# STM32H533 register map
File version: 1.3
CPU: CM33 r0p0, little endian, MPU, FPU, 4 interrupt priority bits
Registers are 32-bit, read-write, reset 0x0 unless marked. A register's access mark holds for its fields unless they carry their own. Offsets are from the block's base; [hi:lo] are bit positions; {n}, {i} and the like mark numbered series; 'fields as' and 'values as' point back to an identical list.

## PWR — PWR address block description
Base 0x44020800
Same registers: PWR_S 0x54020800
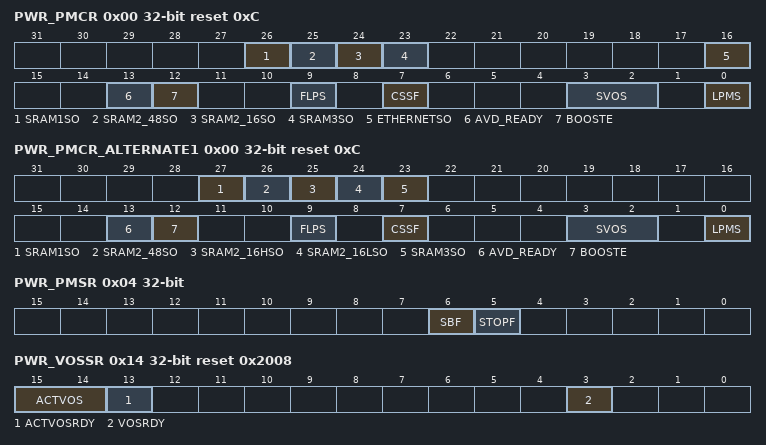
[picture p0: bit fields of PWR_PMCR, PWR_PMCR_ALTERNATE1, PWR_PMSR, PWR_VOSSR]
0x00 PWR_PMCR reset 0xC — PWR power mode control register
  [26] SRAM1SO — AHB SRAM1 shut-off in Stop mode
    0=AHB RA; 1=AHB RAM1 content is lost in Stop mode
  [25] SRAM2_48SO — AHB SRAM2 48-Kbyte shut-off in Stop mode.
    0=AHB RAM2 48-Kbyte content is kept in Stop mode; 1=AHB RAM2 48-Kbyte content is lost in Stop mode
  [24] SRAM2_16SO — AHB SRAM2 16-Kbyte shut-off in Stop mode.
    0=AHB RAM2 16-Kbyte content is kept in Stop mode; 1=AHB RAM2 16-Kbyte content is lost in Stop mode
  [23] SRAM3SO — AHB SRAM3 shut-off in Stop mode.
    0=AHB RAM3 content is kept in Stop mode; 1=AHB RAM3 content is lost in Stop mode
  [16] ETHERNETSO — ETHERNET RAM shut-off in Stop mode.
    0=ETHERNET RAM content is kept in Stop mode; 1=ETHERNET RAM content is lost in Stop mode
  [13] AVD_READY — analog voltage ready
    0=peripheral analog voltage Vless thansub>DDAless than/sub> not ready (default); 1=peripheral analog voltage Vless thansub>DDAless than/sub> ready
  [12] BOOSTE — analog switch Vless thansub>BOOSTless than/sub> control
    0=booster disabled (default); 1=booster enabled if analog voltage ready (AVD_READY = 1)
  [9] FLPS — flash memory low-power mode in Stop mode
    0=flash memory remains in normal mode when the system enters Stop mode (quick restart time); 1=flash memory enters low-power mode when the system enters Stop mode(low-power consumption)
  [7] CSSF — clear Standby and Stop flags (always read as 0)
    0=no effect; 1=STOPF and SBF flags cleared
  [3:2] SVOS — system Stop mode voltage scaling selection
    1=SVOS5 scale 5; 2=SVOS4 scale 4; 3=SVOS3 scale 3 (default)
  [0] LPMS — low-power mode selection
    0=keeps Stop mode when entering DeepSleep; 1=allows Standby mode when entering DeepSleep
0x00 PWR_PMCR_ALTERNATE1 reset 0xC (alternate view of PWR_PMCR) — PWR power mode control register
  [27] SRAM1SO — AHB SRAM1 shut-off in Stop mode
    0=AHB RA; 1=AHB RAM1 content is lost in Stop mode
  [26] SRAM2_48SO — AHB SRAM2 48-Kbyte shut-off in Stop mode.
    values as PWR_PMCR.SRAM2_48SO
  [25] SRAM2_16HSO — AHB SRAM2 high 16-Kbyte shut-off in Stop mode.
    0=AHB RAM2 high 16-Kbyte content is kept in Stop mode; 1=AHB RAM2 ]high16-Kbyte content is lost in Stop mode
  [24] SRAM2_16LSO — AHB SRAM2 low 16-Kbyte shut-off in Stop mode.
    0=AHB RAM2 low 16-Kbyte content is kept in Stop mode; 1=AHB RAM2 low 16-Kbyte content is lost in Stop mode
  [23] SRAM3SO — AHB SRAM3 shut-off in Stop mode.
    values as PWR_PMCR.SRAM3SO
  [13] AVD_READY — analog voltage ready
    values as PWR_PMCR.AVD_READY
  [12] BOOSTE — analog switch Vless thansub>BOOSTless than/sub> control
    values as PWR_PMCR.BOOSTE
  [9] FLPS — flash memory low-power mode in Stop mode
    values as PWR_PMCR.FLPS
  [7] CSSF — clear Standby and Stop flags (always read as 0)
    0=no effect; 1=STOPF and SBF flags cleared
  [3:2] SVOS — system Stop mode voltage scaling selection
    1=SVOS5 scale 5; 2=SVOS4 scale 4; 3=SVOS3 scale 3 (default)
  [0] LPMS — low-power mode selection
    values as PWR_PMCR.LPMS
0x04 PWR_PMSR ro — PWR status register
  [6] SBF — System standby flag
    0=system has not been in Standby mode; 1=system has been in Standby mode
  [5] STOPF — Stop flag
    0=system has not been in Stop mode; 1=system has been in Stop mode
0x10 PWR_VOSCR — PWR voltage scaling control register
  [5:4] VOS — voltage scaling selection according to performance
    0=scale 3 (default); 1=scale 2; 2=scale 1; 3=scale 0
0x14 PWR_VOSSR ro reset 0x2008 — PWR voltage scaling status register
  [15:14] ACTVOS — voltage output scaling currently applied to Vless thansub>COREless than/sub>
    0=VOS3 (lowest power); 1=VOS2; 2=VOS1; 3=VOS0 (highest frequency)
  [13] ACTVOSRDY — Voltage level ready for currently used VOS
    0=Vless thansub>COREless than/sub> is above or below the current voltage scaling provided by ACTVOS[1:0]; 1=Vless thansub>COREless than/sub> is equal to the current voltage scaling provided by ACTVOS[1:0]
  [3] VOSRDY — Ready bit for Vless thansub>COREless than/sub> voltage scaling output selection.
    0=Not ready, voltage level below VOS selected level; 1=Ready, voltage level at or above VOS selected level
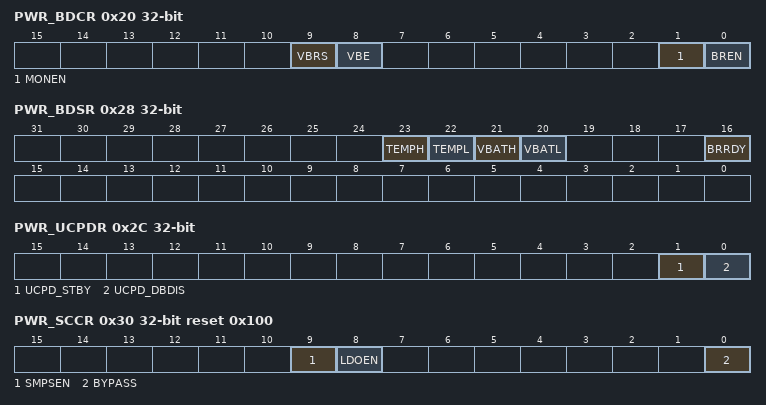
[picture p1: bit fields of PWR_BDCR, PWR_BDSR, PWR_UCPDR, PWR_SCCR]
0x20 PWR_BDCR — PWR Backup domain control register
  [9] VBRS — Vless thansub>BATless than/sub> charging resistor selection
    0=Charge Vless thansub>BATless than/sub> through a 5 kohm resistor; 1=Charge Vless thansub>BATless than/sub> through a 1
  [8] VBE — Vless thansub>BATless than/sub> charging enable
    0=Vless thansub>BATless than/sub> battery charging disabled; 1=Vless thansub>BATless than/sub> battery charging enabled
  [1] MONEN — Backup domain voltage and temperature monitoring enable
    0=Backup domain voltage and temperature monitoring disabled; 1=Backup domain voltage and temperature monitoring enabled
  [0] BREN — Backup RAM retention in Standby and Vless thansub>BATless than/sub> modes
    0=Backup RAM content lost in Standby and Vless thansub>BATless than/sub> modes; 1=Backup RAM content preserved in Standby and Vless thansub>BATless than/sub> modes
0x24 PWR_DBPCR — PWR Backup domain control register
  [0] DBP — Disable Backup domain write protection
    0=Write access to Backup domain disabled; 1=Write access to Backup domain enabled
0x28 PWR_BDSR ro — PWR Backup domain status register
  [23] TEMPH — temperature level monitoring versus high threshold
    0=temperature below high threshold level; 1=temperature equal or above high threshold level
  [22] TEMPL — temperature level monitoring versus low threshold
    0=temperature above low threshold level; 1=temperature equal or below low threshold level
  [21] VBATH — Vless thansub>BATless than/sub> level monitoring versus high threshold
    0=Vless thansub>BATless than/sub> level below high threshold level; 1=Vless thansub>BATless than/sub> level equal or above high threshold level
  [20] VBATL — Vless thansub>BATless than/sub> level monitoring versus low threshold
    0=Vless thansub>BATless than/sub> level above low threshold level; 1=Vless thansub>BATless than/sub> level equal or below low threshold level
  [16] BRRDY — backup regulator ready
    0=backup regulator not ready; 1=backup regulator ready
0x2C PWR_UCPDR — PWR USB Type-C power delivery register
  [1] UCPD_STBY — USB Type-c and Power delivery Standby mode
  [0] UCPD_DBDIS — USB Type-C and power delivery dead battery disable
    0=Enable USB Type-C dead battery pull-down behavior on UCPDx_CC1 and UCPDx_CC2 pins; 1=Disable USB Type-C dead battery pull-down behavior on UCPDx_CC1 and UCPDx_CC2 pins
0x30 PWR_SCCR rw-once reset 0x100 — PWR supply configuration control register
  [9] SMPSEN ro — SMPS enable
  [8] LDOEN ro — LDO enable
  [0] BYPASS — power management unit bypass
    0=Power management unit normal operation; 1=Power management unit bypassed
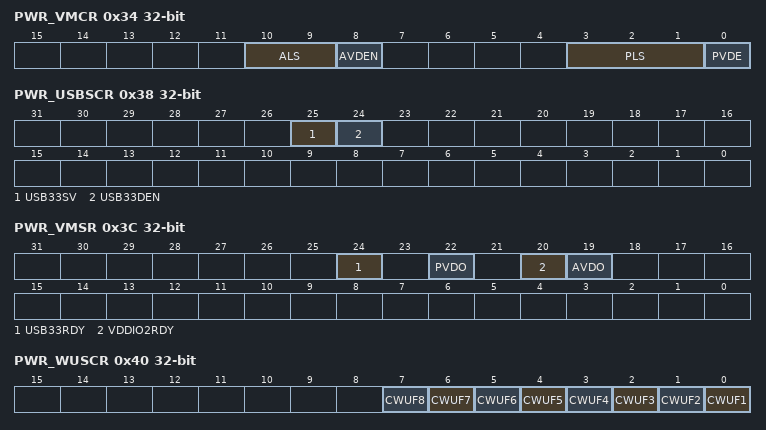
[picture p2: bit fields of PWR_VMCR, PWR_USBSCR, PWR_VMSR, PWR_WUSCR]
0x34 PWR_VMCR — PWR voltage monitor control register
  [10:9] ALS — analog voltage detector (AVD) level selection
    0=AVD level0 (Vless thansub>AVD0less than/sub> ~ 1; 1=AVD level1 (Vless thansub>AVD1less than/sub> ~ 2; 2=AVD level2 (Vless thansub>AVD2less than/sub> ~ 2; 3=AVD level3 (Vless thansub>AVD3less than/sub> ~ 2
  [8] AVDEN — peripheral voltage monitor on Vless thansub>DDAless than/sub> enable
    0=peripheral voltage monitor on Vless thansub>DDAless than/sub> disabled; 1=peripheral voltage monitor on Vless thansub>DDAless than/sub> enabled
  [3:1] PLS — programmable voltage detector (PVD) level selection
    0=PVD level0 (VPVD0 ~ 1; {v}=PVD level{v} (VPVD{v} ~ 2 (v=1..6); 7=PVD_IN pin
  [0] PVDE — PVD enable
    0=PVD disabled; 1=PVD enabled
0x38 PWR_USBSCR — PWR USB supply control register
  [25] USB33SV — independent USB supply valid
    0=Vless thansub>DDUSBless than/sub> is not present; 1=Vless thansub>DDUSBless than/sub> is valid
  [24] USB33DEN — Vless thansub>DDUSBless than/sub> voltage level detector enable
    0=Vless thansub>DDUSBless than/sub> voltage level detector disabled; 1=Vless thansub>DDUSBless than/sub> voltage level detector enabled
0x3C PWR_VMSR ro (reset mask 0xFF0FFFFF) — PWR voltage monitor status register
  [24] USB33RDY — Vless thansub>DDUSBless than/sub> ready
    0=Vless thansub>DDUSBless than/sub> is below the threshold of the Vless thansub>DDUSBless than/sub> voltage monitor; 1=Vless thansub>DDUSBless than/sub> is equal or above the threshold of the Vless thansub>DDUSBless than/sub> voltage monitor
  [22] PVDO — programmable voltage detect output
    0=Vless thansub>DDless than/sub> is equal or higher than the PVD threshold selected through the PLS[2:0] bits; 1=Vless thansub>DDless than/sub> is lower than the PVD threshold selected through the PLS[2:0] bits
  [20] VDDIO2RDY — voltage detector output on Vless thansub>DDIO2less than/sub>
    0=Vless thansub>DDIO2less than/sub> is below 1; 1=Vless thansub>DDIO2less than/sub> is above or equal to 1
  [19] AVDO — analog voltage detector output on Vless thansub>DDAless than/sub>
    0=Vless thansub>DDAless than/sub> is equal or higher than the AVD threshold selected with the ALS[2:0] bits; 1=Vless thansub>DDAless than/sub> is lower than the AVD threshold selected with the ALS[2:0] bits
0x40 PWR_WUSCR wo — PWR wake-up status clear register
  [all] fields
    0=no effect; 1=writing 1 clears the WUFx wake-up pin flag (bit is cleared to 0 by hardware)
  [n-1] CWUF{n} (n=1..8) — clear wake-up pin flag for WUFx (x = 8 to 1)
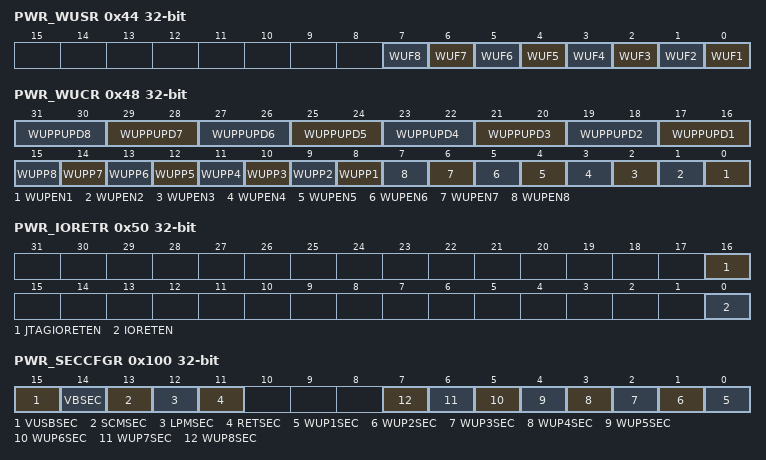
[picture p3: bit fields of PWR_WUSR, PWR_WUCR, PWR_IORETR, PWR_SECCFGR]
0x44 PWR_WUSR ro — PWR wake-up status register
  [all] fields
    0=no wake-up event occurred; 1=wake-up event received from WUFx pin
  [n-1] WUF{n} (n=1..8) — wake-up pin WUFx flag
0x48 PWR_WUCR — PWR wake-up configuration register
  [2n+15:2n+14] WUPPUPD{n} (n=1..8) — wake-up pin pull configuration for WKUPx (x = 8 to 1)
    0=no pull-up; 1=pull-up; 2=pull-down
  [n+7] WUPP{n} (n=1..8) — wake-up pin polarity bit for WUPx (x = 8 to 1)
    0=detection on high level (rising edge); 1=detection on low level (falling edge)
  [n-1] WUPEN{n} (n=1..8) — enable wake-up pin WUPx (x = 8 to 1)
    0=an event on WUPx pin does not wake-up the system from Standby mode; 1=a rising or falling edge on WUPx pin wakes up the system from Standby mode
0x50 PWR_IORETR — PWR I/O retention register
  [16] JTAGIORETEN — IO retention enable for JTAG IOs
    0=IO Retention mode is disabled; 1=IO Retention mode is enabling for PA13, PA14, PA15, and PB4
  [0] IORETEN — IO retention enable
    0=IO Retention mode is disabled; 1=IO Retention mode is enabling for all IO except the IO support the standby functionality and PA13, PA14, PA15, and PB4
0x100 PWR_SECCFGR — PWR security configuration register
  [15] VUSBSEC — voltage USB secure protection
    0=PWR_USBSCR can be read and written with secure or non-secure access; 1=PWR_USBSCR can be read and written only with secure access
  [14] VBSEC — Backup domain secure protection
    0=PWR_BDCR, PWR_DBPCR can be read and written with secure or non-secure access; 1=PWR_BDCR, PWR_DBPCR can be read and written only with secure access
  [13] SCMSEC — supply configuration and monitoring secure protection.
    0=PWR_SCCR and PWR_VMCR can be read and written with secure or non-secure access; 1=PWR_SCCR and PWR_VMCR can be read and written only with secure access
  [12] LPMSEC — low-power modes secure protection
    0=PWR_PMCR can be read and written with secure or non-secure access; 1=PWR_PMCR can be read and written only with secure access
  [11] RETSEC — retention secure protection
    0=PWR_IORETR can be read and written with secure or non-secure access; 1=PWR_IORETR can be read and written only with secure access
  [n-1] WUP{n}SEC (n=1..8) — WUPx secure protection (x = 8 to 1)
    0=The bits related to the WKUPx wake-up pin in PWR_WUSCR and PWR_WUCR can be read and written with secure or non-secure access; 1=The bits related to the WKUPx wake-up pin in PWR_WUSCR and PWR_WUCR can be read and written only with secure access
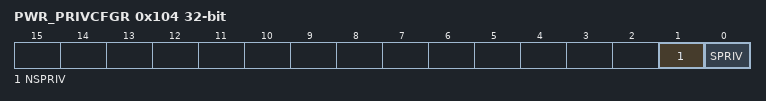
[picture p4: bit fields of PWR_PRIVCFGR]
0x104 PWR_PRIVCFGR — PWR privilege configuration register
  [1] NSPRIV — PWR non-secure functions privilege configuration
    0=Read and write to PWR non-secure functions can be done by privileged or unprivileged access; 1=Read and write to PWR non-secure functions can be done by privileged access only
  [0] SPRIV — PWR secure functions privilege configuration
    0=Read and write to PWR secure functions can be done by privileged or unprivileged access; 1=Read and write to PWR secure functions can be done by privileged access only
